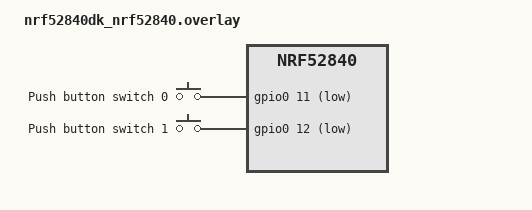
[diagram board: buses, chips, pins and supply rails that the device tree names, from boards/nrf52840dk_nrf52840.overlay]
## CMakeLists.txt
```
cmake_minimum_required(VERSION 3.20.0)
find_package(Zephyr REQUIRED HINTS $ENV{ZEPHYR_BASE})

project(
    Demo
    VERSION 0.1
    DESCRIPTION "Demo."
)

target_sources(
    app
    PRIVATE
    src/main.c
)
```

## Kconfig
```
# Application Kconfig entry point.

menu "Zephyr"
source "Kconfig.zephyr"
endmenu

# module = APP
# module-str = APP
# source "subsys/logging/Kconfig.template.log_config"
```

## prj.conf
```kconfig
# prj.conf is usually used for debugging.
# The build type prj_release.conf is typically used for release builds.
# Thus, we can explicitly enable debugging for better step debugging.

# Enable kernel debugging, this also sets CONFIG_DEBUG_OPTIMIZATIONS.
CONFIG_DEBUG=y
# Build for debugging by default.
CONFIG_DEBUG_OPTIMIZATIONS=y
# Enable assertions
CONFIG_ASSERT=y
# Enable shell
CONFIG_SHELL=y

# CPP support
CONFIG_CPP=y
CONFIG_STD_CPP17=y

# Logging
CONFIG_LOG=y
# CONFIG_LOG_MODE_MINIMAL=y

# Input subsystem
CONFIG_INPUT=y
# CONFIG_INPUT_EVENT_DUMP=y
# Input longpress subsystem
# CONFIG_INPUT_LONGPRESS=y
# Enable the input shell
CONFIG_INPUT_SHELL=y

# Don't build the development kit library
# CONFIG_DK_LIBRARY=y
```

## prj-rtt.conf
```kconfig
CONFIG_USE_SEGGER_RTT=y

CONFIG_SHELL_BACKEND_SERIAL=n
CONFIG_SHELL_BACKEND_RTT=y

CONFIG_LOG_MODE_MINIMAL=n
CONFIG_LOG_PRINTK=y
CONFIG_RTT_CONSOLE=y
CONFIG_LOG_BACKEND_UART=n
# can't use 'LOG_BACKEND_RTT' unless separate RAM buffers are configured
# CONFIG_LOG_BACKEND_RTT=y
# therefore, use the SHELL backend also for logging.
CONFIG_SHELL_LOG_BACKEND=y
```

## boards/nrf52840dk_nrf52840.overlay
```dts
/ {
  chosen {};

  buttons: buttons {
    compatible = "gpio-keys";

    button0: button_0 {
      gpios = <&gpio0 11 (GPIO_PULL_UP | GPIO_ACTIVE_LOW)>;
      label = "Push button switch 0";
      zephyr,code = <INPUT_KEY_0>;
    };

    button1: button_1 {
      gpios = <&gpio0 12 (GPIO_PULL_UP | GPIO_ACTIVE_LOW)>;
      label = "Push button switch 1";
      zephyr,code = <INPUT_KEY_1>;
    };
  };
};
```

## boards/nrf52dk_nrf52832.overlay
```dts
/ {
  chosen {};

  buttons: buttons {
    compatible = "gpio-keys";

    button0: button_0 {
      gpios = <&gpio0 13 (GPIO_PULL_UP | GPIO_ACTIVE_LOW)>;
      label = "Push button switch 0";
      zephyr,code = <INPUT_KEY_0>;
    };

    button1: button_1 {
      gpios = <&gpio0 14 (GPIO_PULL_UP | GPIO_ACTIVE_LOW)>;
      label = "Push button switch 1";
      zephyr,code = <INPUT_KEY_1>;
    };
  };
};
```

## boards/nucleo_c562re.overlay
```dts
/ {
    chosen {};

    buttons: buttons {
        compatible = "gpio-keys";

        button0: button_0 {
            label = "Push button switch 0";
            gpios = <&gpioc 13 GPIO_ACTIVE_LOW>;
            zephyr,code = <INPUT_KEY_0>;
        };
    };
};
```

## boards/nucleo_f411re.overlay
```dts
/ {
    chosen {
    };

    buttons: buttons {
        compatible = "gpio-keys";
        button0: button_0 {
            label = "Push button switch 0";
            gpios = <&gpioc 13 GPIO_ACTIVE_LOW>;
            zephyr,code = <INPUT_KEY_0>;
        };
    };
};
```

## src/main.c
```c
#include <stdlib.h>

#include <zephyr/drivers/gpio.h>
#include <zephyr/input/input.h>
#include <zephyr/kernel.h>
#include <zephyr/shell/shell.h>

#include <zephyr/logging/log.h>
LOG_MODULE_REGISTER(app, LOG_LEVEL_DBG);

/*******************************************************************************
 * Definitions
 ******************************************************************************/

#define SLEEP_TIME_MS 1000U

#define DT_PROP_OR_EMPTY(node_id, prop) \
    COND_CODE_1(DT_NODE_HAS_PROP(node_id, prop), (DT_PROP(node_id, prop), ), ())

static void prv_handle_button(int32_t const value);

static void prv_input_cb_buttons(struct input_event *evt, void *user_data);

static int prv_shell_simulate_button(
    const struct shell *sh, size_t argc, char **argv);

/*******************************************************************************
 * Data
 ******************************************************************************/

static struct device const *const buttons_dev = DEVICE_DT_GET(
    DT_NODELABEL(buttons));

static struct gpio_dt_spec const led0 = GPIO_DT_SPEC_GET(DT_ALIAS(led0), gpios);

// clang-format off
static uint16_t const button_codes[] = {
    DT_PROP_OR_EMPTY(DT_NODELABEL(button0), zephyr_code)
    DT_PROP_OR_EMPTY(DT_NODELABEL(button1), zephyr_code)
};
// clang-format on

static bool light_is_on = false;

// to use the input shell, e.g., `input report 1 11 1`, the
// device has to be NULL since the input shell doesn't allow reporting
// for a specific device
INPUT_CALLBACK_DEFINE(NULL, prv_input_cb_buttons, NULL);

/*******************************************************************************
 * Functions
 ******************************************************************************/

static void prv_handle_button(int32_t const value)
{
    // the event's value is > 0 if the button is being pressed.
    // toggle the light on button press, don't do anything on release.
    if (value > 0)
    {
        light_is_on = !light_is_on;
        int ret     = gpio_pin_set_dt(&led0, light_is_on ? 1 : 0);
        LOG_INF("led is %s", light_is_on ? "ON" : "OFF");
        __ASSERT_NO_MSG(ret >= 0);
    }
}

static void prv_input_cb_buttons(struct input_event *evt, void *user_data)
{
    __ASSERT_NO_MSG(evt != NULL);
    (void) user_data;

    LOG_INF(
        "input device '%s', zephyr_code=%u, value=%d\n",
        evt->dev->name,
        evt->code,
        evt->value);

    for (size_t i = 0U; i < ARRAY_SIZE(button_codes); i++)
    {
        if (evt->code == button_codes[i])
        {
            prv_handle_button(evt->value);
        }
    }
}

int main(void)
{
    (void) buttons_dev;
    bool tick = true;

    printk("running demo built for board %s\n", CONFIG_BOARD_TARGET);

    bool ready = gpio_is_ready_dt(&led0);
    __ASSERT_NO_MSG(ready);

    int ret = gpio_pin_configure_dt(&led0, GPIO_OUTPUT_ACTIVE);
    __ASSERT_NO_MSG(ret >= 0);

    ret = gpio_pin_set_dt(&led0, 0);
    __ASSERT_NO_MSG(ret >= 0);

    while (1)
    {
        k_msleep(1000U);
        (void) k_msleep(SLEEP_TIME_MS);

        if (tick != false)
        {
            printk("Tick\n");
        }
        else
        {
            printk("Tock\n");
        }
        tick = !tick;
    }
}

static int prv_shell_simulate_button(
    const struct shell *sh, size_t argc, char **argv)
{
    (void) argc;
    char *end_ptr;

    // strtoul also parses hexadecimal numbers
    const unsigned long arg_value = strtoul(argv[1], &end_ptr, 0);
    if (*end_ptr != '\0')
    {
        shell_error(sh, "invalid parameter '%s' for value", argv[1]);
        return -EINVAL;
    }

    if (arg_value > UINT32_MAX)
    {
        shell_error(
            sh,
            "value %lu is out of its allowed range [0x0, 0x%lx]",
            arg_value,
            UINT32_MAX);
        return -EINVAL;
    }

    shell_print(sh, "simulating button value %lu", arg_value);
    prv_handle_button(arg_value);
    return 0;
}

SHELL_STATIC_SUBCMD_SET_CREATE(
    sub_cmd,
    SHELL_CMD_ARG(
        simulate_button,
        NULL,
        "simulate button value",
        prv_shell_simulate_button,
        2,
        0),
    SHELL_SUBCMD_SET_END);

SHELL_CMD_REGISTER(
    demo, &sub_cmd, "demo for an application command with sub commands", NULL);
```
